VERSION ""

NS_ :

BS_:

BU_: DBG VCU BMS MCM DAQ

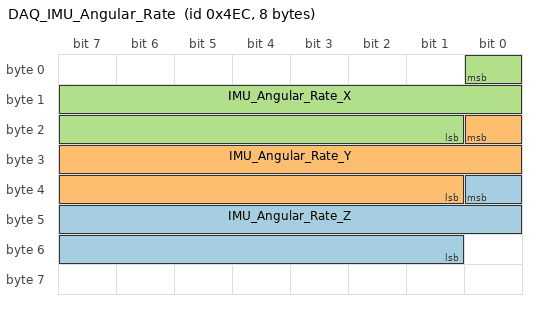
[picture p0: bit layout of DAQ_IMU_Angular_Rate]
BO_ 1260 DAQ_IMU_Angular_Rate: 8 DAQ
 SG_ IMU_Angular_Rate_Z : 32|16@0- (0.001,0) [-250|250] "dps" DAQ
 SG_ IMU_Angular_Rate_Y : 16|16@0- (0.001,0) [-250|250] "dps" DAQ
 SG_ IMU_Angular_Rate_X : 0|16@0- (0.001,0) [-250|250] "dps" DAQ

BO_ 1261 DAQ_IMU_Acceleration: 8 DAQ
 SG_ IMU_Temperature : 48|16@0- (0.01,0) [-10|10] "C" DAQ
 SG_ IMU_Acceleration_Z : 32|16@0- (0.0001,0) [-10|10] "g" DAQ
 SG_ IMU_Acceleration_Y : 16|16@0- (0.0001,0) [-10|10] "g" DAQ
 SG_ IMU_Acceleration_X : 0|16@0- (0.0001,0) [-10|10] "g" DAQ

CM_ BU_ VCU "The vehicle control unit";
CM_ BU_ MCM "The motor controller of the car";
CM_ BU_ BMS "The battery management system";
CM_ BU_ DAQ "The data acquisition unit";
CM_ BO_ 1260 "IMU Angular Rate";
CM_ BO_ 1261 "IMU Acceleration";

BA_DEF_ "BusType" STRING ;
BA_DEF_ SG_ "FieldType" STRING ;

BA_DEF_DEF_ "BusType" "CAN";
BA_DEF_DEF_ "FieldType" "";

BA_ "FieldType" SG_ 100 DRIVER_HEARTBEAT_cmd "DRIVER_HEARTBEAT_cmd";

VAL_ 100 DRIVER_HEARTBEAT_cmd 2 "DRIVER_HEARTBEAT_cmd_REBOOT" 1 "DRIVER_HEARTBEAT_cmd_SYNC" 0 "DRIVER_HEARTBEAT_cmd_NOOP" ;
